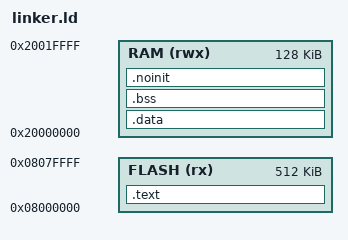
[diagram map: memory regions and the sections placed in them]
ENTRY(Reset_Handler)

MEMORY
{
    FLASH (rx)  : ORIGIN = 0x08000000, LENGTH = 512K
    RAM   (rwx) : ORIGIN = 0x20000000, LENGTH = 128K
}

SECTIONS
{
    .text :
    {
        KEEP(*(.isr_vector))
        *(.text*)
        *(.rodata*)
        . = ALIGN(4);
    } > FLASH

    .data : AT (ADDR(.text) + SIZEOF(.text))
    {
        . = ALIGN(4);
        *(.data*)
        . = ALIGN(4);
    } > RAM

    .bss :
    {
        . = ALIGN(4);
        *(.bss*)
        *(COMMON)
        . = ALIGN(4);
    } > RAM

    .noinit (NOLOAD) :
    {
        . = ALIGN(4);
        *(.noinit*)
        . = ALIGN(4);
    } > RAM

    _end = .;
}
_estack = ORIGIN(RAM) + LENGTH(RAM);
